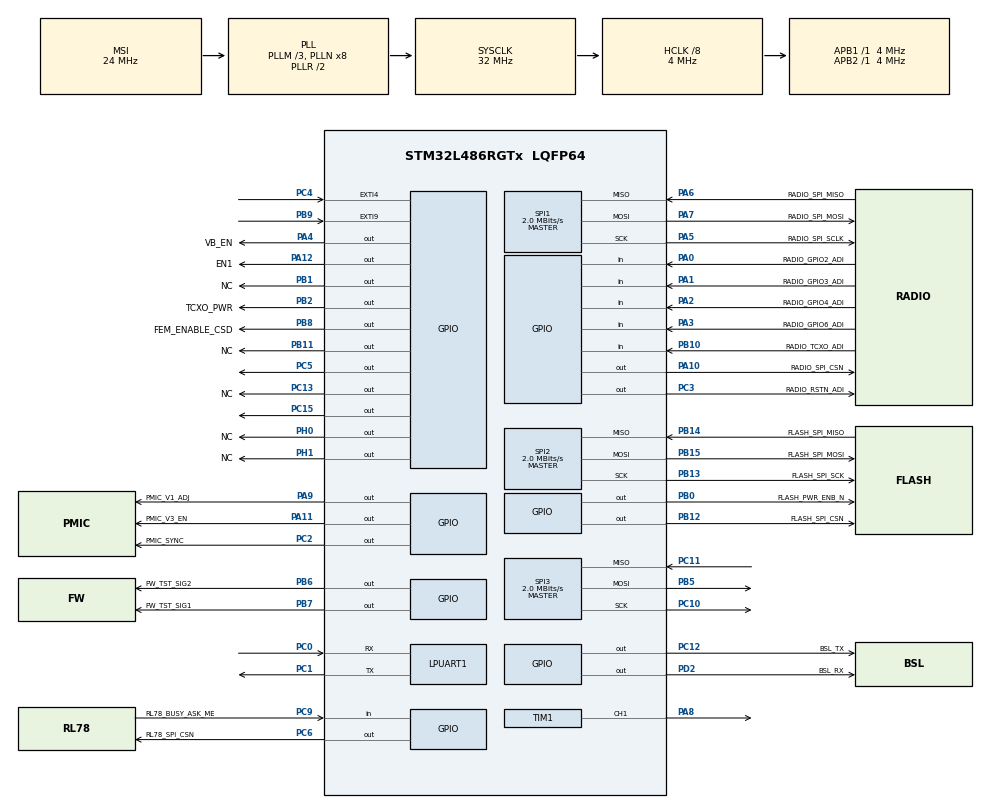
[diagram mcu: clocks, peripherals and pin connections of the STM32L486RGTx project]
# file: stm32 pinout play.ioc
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ADC1.Channel-0\#ChannelRegularConversion=ADC_CHANNEL_TEMPSENSOR
ADC1.NbrOfConversionFlag=1
ADC1.OffsetNumber-0\#ChannelRegularConversion=ADC_OFFSET_NONE
ADC1.Rank-0\#ChannelRegularConversion=1
ADC1.SamplingTime-0\#ChannelRegularConversion=ADC_SAMPLETIME_2CYCLES_5
ADC1.master=1
Mcu.Family=STM32L4
Mcu.Name=STM32L486RGTx
Mcu.Package=LQFP64
NVIC.EXTI4_IRQn=true\:0\:0\:false\:false\:true\:true
NVIC.PriorityGroup=NVIC_PRIORITYGROUP_4
PA0.GPIO_Label=RADIO_GPIO2_ADI
PA0.Signal=GPIO_Input
PA1.GPIO_Label=RADIO_GPIO3_ADI
PA1.Signal=GPIO_Input
PA10.GPIO_Label=RADIO_SPI_CSN
PA10.Signal=GPIO_Output
PA11.GPIO_Label=PMIC_V3_EN
PA11.Signal=GPIO_Output
PA12.GPIO_Label=EN1
PA12.Signal=GPIO_Output
PA13\ (JTMS-SWDIO).Mode=JTAG_5_pins
PA13\ (JTMS-SWDIO).Signal=SYS_JTMS-SWDIO
PA14\ (JTCK-SWCLK).Mode=JTAG_5_pins
PA14\ (JTCK-SWCLK).Signal=SYS_JTCK-SWCLK
PA15\ (JTDI).Mode=JTAG_5_pins
PA15\ (JTDI).Signal=SYS_JTDI
PA2.GPIO_Label=RADIO_GPIO4_ADI
PA2.Signal=GPIO_Input
PA3.GPIO_Label=RADIO_GPIO6_ADI
PA3.Signal=GPIO_Input
PA4.GPIO_Label=VB_EN
PA4.GPIO_PuPd=GPIO_PULLDOWN
PA4.GPIO_Speed=GPIO_SPEED_FREQ_LOW
PA4.Signal=GPIO_Output
PA5.GPIO_Label=RADIO_SPI_SCLK
PA5.Mode=Full_Duplex_Master
PA5.Signal=SPI1_SCK
PA6.GPIO_Label=RADIO_SPI_MISO
PA6.Mode=Full_Duplex_Master
PA6.Signal=SPI1_MISO
PA7.GPIO_Label=RADIO_SPI_MOSI
PA7.Mode=Full_Duplex_Master
PA7.Signal=SPI1_MOSI
PA8.Signal=S_TIM1_CH1
PA9.GPIO_Label=PMIC_V1_ADJ
PA9.GPIO_PuPd=GPIO_PULLDOWN
PA9.Signal=GPIO_Output
PB0.GPIO_Label=FLASH_PWR_ENB_N
PB0.PinState=GPIO_PIN_SET
PB0.Signal=GPIO_Output
PB1.GPIO_Label=NC
PB1.GPIO_PuPd=GPIO_PULLDOWN
PB1.Signal=GPIO_Output
PB10.GPIO_Label=RADIO_TCXO_ADI
PB10.GPIO_PuPd=GPIO_PULLDOWN
PB10.Signal=GPIO_Input
PB11.GPIO_Label=NC
PB11.GPIO_PuPd=GPIO_PULLDOWN
PB11.Signal=GPIO_Output
PB12.GPIO_Label=FLASH_SPI_CSN
PB12.Signal=GPIO_Output
PB13.GPIO_Label=FLASH_SPI_SCK
PB13.Mode=Full_Duplex_Master
PB13.Signal=SPI2_SCK
PB14.GPIO_Label=FLASH_SPI_MISO
PB14.Mode=Full_Duplex_Master
PB14.Signal=SPI2_MISO
PB15.GPIO_Label=FLASH_SPI_MOSI
PB15.Mode=Full_Duplex_Master
PB15.Signal=SPI2_MOSI
PB2.GPIO_Label=TCXO_PWR
PB2.PinState=GPIO_PIN_RESET
PB2.Signal=GPIO_Output
PB3\ (JTDO-TRACESWO).Mode=JTAG_5_pins
PB3\ (JTDO-TRACESWO).Signal=SYS_JTDO-SWO
PB4\ (NJTRST).Mode=JTAG_5_pins
PB4\ (NJTRST).Signal=SYS_JTRST
PB5.Mode=Full_Duplex_Master
PB5.Signal=SPI3_MOSI
PB6.GPIO_Label=FW_TST_SIG2
PB6.GPIO_PuPd=GPIO_PULLDOWN
PB6.Signal=GPIO_Output
PB7.GPIO_Label=FW_TST_SIG1
PB7.GPIO_PuPd=GPIO_PULLDOWN
PB7.Signal=GPIO_Output
PB8.GPIO_Label=FEM_ENABLE_CSD
PB8.GPIO_PuPd=GPIO_PULLDOWN
PB8.Signal=GPIO_Output
PB9.Signal=GPXTI9
PC0.Mode=Asynchronous
PC0.Signal=LPUART1_RX
PC1.Mode=Asynchronous
PC1.Signal=LPUART1_TX
PC10.Mode=Full_Duplex_Master
PC10.Signal=SPI3_SCK
PC11.Mode=Full_Duplex_Master
PC11.Signal=SPI3_MISO
PC12.GPIO_Label=BSL_TX
PC12.GPIO_PuPd=GPIO_PULLDOWN
PC12.Signal=GPIO_Output
PC13.GPIO_Label=NC
PC13.GPIO_PuPd=GPIO_PULLDOWN
PC13.Signal=GPIO_Output
PC14-OSC32_IN\ (PC14).Mode=LSE-External-Clock-Source
PC14-OSC32_IN\ (PC14).Signal=RCC_OSC32_IN
PC15-OSC32_OUT\ (PC15).Signal=GPIO_Output
PC2.GPIO_Label=PMIC_SYNC
PC2.GPIO_ModeDefaultOutputPP=GPIO_MODE_OUTPUT_PP
PC2.Signal=GPIO_Output
PC3.GPIO_Label=RADIO_RSTN_ADI
PC3.Signal=GPIO_Output
PC4.Signal=GPXTI4
PC5.GPIO_PuPd=GPIO_PULLDOWN
PC5.Signal=GPIO_Output
PC6.GPIO_Label=RL78_SPI_CSN
PC6.GPIO_PuPd=GPIO_PULLDOWN
PC6.Signal=GPIO_Output
PC7.Signal=S_TIM3_CH2
PC8.Signal=S_TIM3_CH3
PC9.GPIO_Label=RL78_BUSY_ASK_ME
PC9.Signal=GPIO_Input
PD2.GPIO_Label=BSL_RX
PD2.GPIO_PuPd=GPIO_PULLDOWN
PD2.Signal=GPIO_Output
PH0-OSC_IN\ (PH0).GPIO_Label=NC
PH0-OSC_IN\ (PH0).GPIO_PuPd=GPIO_PULLDOWN
PH0-OSC_IN\ (PH0).Signal=GPIO_Output
PH1-OSC_OUT\ (PH1).GPIO_Label=NC
PH1-OSC_OUT\ (PH1).GPIO_PuPd=GPIO_PULLDOWN
PH1-OSC_OUT\ (PH1).Signal=GPIO_Output
ProjectManager.HeapSize=0x200
ProjectManager.StackSize=0x400
ProjectManager.TargetToolchain=MDK-ARM V5
RCC.ADCFreq_Value=64000000
RCC.AHBCLKDivider=RCC_SYSCLK_DIV8
RCC.AHBFreq_Value=4000000
RCC.APB1Freq_Value=4000000
RCC.APB1TimFreq_Value=4000000
RCC.APB2Freq_Value=4000000
RCC.APB2TimFreq_Value=4000000
RCC.CortexFreq_Value=4000000
RCC.HCLKFreq_Value=4000000
RCC.HSE_VALUE=8000000
RCC.HSI_VALUE=16000000
RCC.MSIClockRange=RCC_MSIRANGE_9
RCC.MSI_VALUE=24000000
RCC.PLLM=3
RCC.PLLSAI1N=16
RCC.RTCClockSelection=RCC_RTCCLKSOURCE_LSE
RCC.SYSCLKFreq_VALUE=32000000
RCC.SYSCLKSource=RCC_SYSCLKSOURCE_PLLCLK
RCC.USBFreq_Value=64000000
RCC.VCOOutputFreq_Value=64000000
SH.S_TIM1_CH1.0=TIM1_CH1,Output Compare1 CH1
SH.S_TIM3_CH2.0=TIM3_CH2
SH.S_TIM3_CH3.0=TIM3_CH3
SPI1.CalculateBaudRate=2.0 MBits/s
SPI1.Direction=SPI_DIRECTION_2LINES
SPI1.Mode=SPI_MODE_MASTER
SPI1.VirtualType=VM_MASTER
SPI2.CalculateBaudRate=2.0 MBits/s
SPI2.Direction=SPI_DIRECTION_2LINES
SPI2.Mode=SPI_MODE_MASTER
SPI2.VirtualType=VM_MASTER
SPI3.CalculateBaudRate=2.0 MBits/s
SPI3.Direction=SPI_DIRECTION_2LINES
SPI3.Mode=SPI_MODE_MASTER
SPI3.VirtualType=VM_MASTER
TIM1.Channel-Output\ Compare1\ CH1=TIM_CHANNEL_1
TIM1.OCMode_1=TIM_OCMODE_RETRIGERRABLE_OPM2
TIM1.Period=8191
TIM1.Pulse-Output\ Compare1\ CH1=8191
VP_ADC1_TempSens_Input.Mode=IN-TempSens
VP_RTC_VS_RTC_Activate.Mode=RTC_Enabled
VP_TIM1_VS_ClockSourceINT.Mode=Internal
board=custom

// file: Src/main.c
/**
  ******************************************************************************
  * @file           : main.c
  * @brief          : Main program body
  ******************************************************************************
  ** This notice applies to any and all portions of this file
  * that are not between comment pairs USER CODE BEGIN and
  * USER CODE END. Other portions of this file, whether
  * inserted by the user or by software development tools
  * are owned by their respective copyright owners.
  *
  * COPYRIGHT(c) 2019 STMicroelectronics
  *
  * Redistribution and use in source and binary forms, with or without modification,
  * are permitted provided that the following conditions are met:
  *   1. Redistributions of source code must retain the above copyright notice,
  *      this list of conditions and the following disclaimer.
  *   2. Redistributions in binary form must reproduce the above copyright notice,
  *      this list of conditions and the following disclaimer in the documentation
  *      and/or other materials provided with the distribution.
  *   3. Neither the name of STMicroelectronics nor the names of its contributors
  *      may be used to endorse or promote products derived from this software
  *      without specific prior written permission.
  *
  * THIS SOFTWARE IS PROVIDED BY THE COPYRIGHT HOLDERS AND CONTRIBUTORS "AS IS"
  * AND ANY EXPRESS OR IMPLIED WARRANTIES, INCLUDING, BUT NOT LIMITED TO, THE
  * IMPLIED WARRANTIES OF MERCHANTABILITY AND FITNESS FOR A PARTICULAR PURPOSE ARE
  * DISCLAIMED. IN NO EVENT SHALL THE COPYRIGHT HOLDER OR CONTRIBUTORS BE LIABLE
  * FOR ANY DIRECT, INDIRECT, INCIDENTAL, SPECIAL, EXEMPLARY, OR CONSEQUENTIAL
  * DAMAGES (INCLUDING, BUT NOT LIMITED TO, PROCUREMENT OF SUBSTITUTE GOODS OR
  * SERVICES; LOSS OF USE, DATA, OR PROFITS; OR BUSINESS INTERRUPTION) HOWEVER
  * CAUSED AND ON ANY THEORY OF LIABILITY, WHETHER IN CONTRACT, STRICT LIABILITY,
  * OR TORT (INCLUDING NEGLIGENCE OR OTHERWISE) ARISING IN ANY WAY OUT OF THE USE
  * OF THIS SOFTWARE, EVEN IF ADVISED OF THE POSSIBILITY OF SUCH DAMAGE.
  *
  ******************************************************************************
  */
#include "main.h"
#include "stm32l4xx_hal.h"

ADC_HandleTypeDef hadc1;

UART_HandleTypeDef hlpuart1;

RTC_HandleTypeDef hrtc;

SPI_HandleTypeDef hspi1;
SPI_HandleTypeDef hspi2;
SPI_HandleTypeDef hspi3;

TIM_HandleTypeDef htim1;

/* USER CODE BEGIN PV */
/* Private variables ---------------------------------------------------------*/

/* USER CODE END PV */

void SystemClock_Config(void);
static void MX_GPIO_Init(void);
static void MX_ADC1_Init(void);
static void MX_LPUART1_UART_Init(void);
static void MX_SPI1_Init(void);
static void MX_SPI2_Init(void);
static void MX_SPI3_Init(void);
static void MX_RTC_Init(void);
static void MX_TIM1_Init(void);

void HAL_TIM_MspPostInit(TIM_HandleTypeDef *htim);

/* USER CODE BEGIN PFP */
/* Private function prototypes -----------------------------------------------*/

/* USER CODE END PFP */

int main(void)
{

  /* MCU Configuration----------------------------------------------------------*/

  /* Reset of all peripherals, Initializes the Flash interface and the Systick. */
  HAL_Init();

  /* Configure the system clock */
  SystemClock_Config();

  /* Initialize all configured peripherals */
  MX_GPIO_Init();
  MX_ADC1_Init();
  MX_LPUART1_UART_Init();
  MX_SPI1_Init();
  MX_SPI2_Init();
  MX_SPI3_Init();
  MX_RTC_Init();
  MX_TIM1_Init();
  /* USER CODE BEGIN 2 */
	HAL_TIM_OC_Start(&htim1, TIM_CHANNEL_1);
  /* USER CODE END 2 */

  /* Infinite loop */
  while (1)
  {

  /* USER CODE BEGIN 3 */
	HAL_GPIO_TogglePin(GPIOC, GPIO_PIN_12);
	HAL_Delay(500);
  }
  /* USER CODE END 3 */

}

void SystemClock_Config(void)
{

  RCC_OscInitTypeDef RCC_OscInitStruct;
  RCC_ClkInitTypeDef RCC_ClkInitStruct;
  RCC_PeriphCLKInitTypeDef PeriphClkInit;

    /**Initializes the CPU, AHB and APB busses clocks
    */
  RCC_OscInitStruct.OscillatorType = RCC_OSCILLATORTYPE_LSE|RCC_OSCILLATORTYPE_MSI;
  RCC_OscInitStruct.LSEState = RCC_LSE_BYPASS;
  RCC_OscInitStruct.MSIState = RCC_MSI_ON;
  RCC_OscInitStruct.MSICalibrationValue = 0;
  RCC_OscInitStruct.MSIClockRange = RCC_MSIRANGE_9;
  RCC_OscInitStruct.PLL.PLLState = RCC_PLL_ON;
  RCC_OscInitStruct.PLL.PLLSource = RCC_PLLSOURCE_MSI;
  RCC_OscInitStruct.PLL.PLLM = 3;
  RCC_OscInitStruct.PLL.PLLN = 8;
  RCC_OscInitStruct.PLL.PLLP = RCC_PLLP_DIV7;
  RCC_OscInitStruct.PLL.PLLQ = RCC_PLLQ_DIV2;
  RCC_OscInitStruct.PLL.PLLR = RCC_PLLR_DIV2;
  if (HAL_RCC_OscConfig(&RCC_OscInitStruct) != HAL_OK)
  {
    _Error_Handler(__FILE__, __LINE__);
  }

    /**Initializes the CPU, AHB and APB busses clocks
    */
  RCC_ClkInitStruct.ClockType = RCC_CLOCKTYPE_HCLK|RCC_CLOCKTYPE_SYSCLK
                              |RCC_CLOCKTYPE_PCLK1|RCC_CLOCKTYPE_PCLK2;
  RCC_ClkInitStruct.SYSCLKSource = RCC_SYSCLKSOURCE_PLLCLK;
  RCC_ClkInitStruct.AHBCLKDivider = RCC_SYSCLK_DIV8;
  RCC_ClkInitStruct.APB1CLKDivider = RCC_HCLK_DIV1;
  RCC_ClkInitStruct.APB2CLKDivider = RCC_HCLK_DIV1;

  if (HAL_RCC_ClockConfig(&RCC_ClkInitStruct, FLASH_LATENCY_0) != HAL_OK)
  {
    _Error_Handler(__FILE__, __LINE__);
  }

  PeriphClkInit.PeriphClockSelection = RCC_PERIPHCLK_RTC|RCC_PERIPHCLK_LPUART1
                              |RCC_PERIPHCLK_ADC;
  PeriphClkInit.Lpuart1ClockSelection = RCC_LPUART1CLKSOURCE_PCLK1;
  PeriphClkInit.AdcClockSelection = RCC_ADCCLKSOURCE_PLLSAI1;
  PeriphClkInit.RTCClockSelection = RCC_RTCCLKSOURCE_LSE;
  PeriphClkInit.PLLSAI1.PLLSAI1Source = RCC_PLLSOURCE_MSI;
  PeriphClkInit.PLLSAI1.PLLSAI1M = 3;
  PeriphClkInit.PLLSAI1.PLLSAI1N = 16;
  PeriphClkInit.PLLSAI1.PLLSAI1P = RCC_PLLP_DIV7;
  PeriphClkInit.PLLSAI1.PLLSAI1Q = RCC_PLLQ_DIV2;
  PeriphClkInit.PLLSAI1.PLLSAI1R = RCC_PLLR_DIV2;
  PeriphClkInit.PLLSAI1.PLLSAI1ClockOut = RCC_PLLSAI1_ADC1CLK;
  if (HAL_RCCEx_PeriphCLKConfig(&PeriphClkInit) != HAL_OK)
  {
    _Error_Handler(__FILE__, __LINE__);
  }

    /**Configure the main internal regulator output voltage
    */
  if (HAL_PWREx_ControlVoltageScaling(PWR_REGULATOR_VOLTAGE_SCALE1) != HAL_OK)
  {
    _Error_Handler(__FILE__, __LINE__);
  }

    /**Configure the Systick interrupt time
    */
  HAL_SYSTICK_Config(HAL_RCC_GetHCLKFreq()/1000);

    /**Configure the Systick
    */
  HAL_SYSTICK_CLKSourceConfig(SYSTICK_CLKSOURCE_HCLK);

    /**Enable MSI Auto calibration
    */
  HAL_RCCEx_EnableMSIPLLMode();

  /* SysTick_IRQn interrupt configuration */
  HAL_NVIC_SetPriority(SysTick_IRQn, 0, 0);
}

/* ADC1 init function */
static void MX_ADC1_Init(void)
{

  ADC_MultiModeTypeDef multimode;
  ADC_ChannelConfTypeDef sConfig;

    /**Common config
    */
  hadc1.Instance = ADC1;
  hadc1.Init.ClockPrescaler = ADC_CLOCK_ASYNC_DIV1;
  hadc1.Init.Resolution = ADC_RESOLUTION_12B;
  hadc1.Init.DataAlign = ADC_DATAALIGN_RIGHT;
  hadc1.Init.ScanConvMode = ADC_SCAN_DISABLE;
  hadc1.Init.EOCSelection = ADC_EOC_SINGLE_CONV;
  hadc1.Init.LowPowerAutoWait = DISABLE;
  hadc1.Init.ContinuousConvMode = DISABLE;
  hadc1.Init.NbrOfConversion = 1;
  hadc1.Init.DiscontinuousConvMode = DISABLE;
  hadc1.Init.ExternalTrigConv = ADC_SOFTWARE_START;
  hadc1.Init.ExternalTrigConvEdge = ADC_EXTERNALTRIGCONVEDGE_NONE;
  hadc1.Init.DMAContinuousRequests = DISABLE;
  hadc1.Init.Overrun = ADC_OVR_DATA_PRESERVED;
  hadc1.Init.OversamplingMode = DISABLE;
  if (HAL_ADC_Init(&hadc1) != HAL_OK)
  {
    _Error_Handler(__FILE__, __LINE__);
  }

    /**Configure the ADC multi-mode
    */
  multimode.Mode = ADC_MODE_INDEPENDENT;
  if (HAL_ADCEx_MultiModeConfigChannel(&hadc1, &multimode) != HAL_OK)
  {
    _Error_Handler(__FILE__, __LINE__);
  }

    /**Configure Regular Channel
    */
  sConfig.Channel = ADC_CHANNEL_TEMPSENSOR;
  sConfig.Rank = ADC_REGULAR_RANK_1;
  sConfig.SamplingTime = ADC_SAMPLETIME_2CYCLES_5;
  sConfig.SingleDiff = ADC_SINGLE_ENDED;
  sConfig.OffsetNumber = ADC_OFFSET_NONE;
  sConfig.Offset = 0;
  if (HAL_ADC_ConfigChannel(&hadc1, &sConfig) != HAL_OK)
  {
    _Error_Handler(__FILE__, __LINE__);
  }

}

/* LPUART1 init function */
static void MX_LPUART1_UART_Init(void)
{

  hlpuart1.Instance = LPUART1;
  hlpuart1.Init.BaudRate = 209700;
  hlpuart1.Init.WordLength = UART_WORDLENGTH_7B;
  hlpuart1.Init.StopBits = UART_STOPBITS_1;
  hlpuart1.Init.Parity = UART_PARITY_NONE;
  hlpuart1.Init.Mode = UART_MODE_TX_RX;
  hlpuart1.Init.HwFlowCtl = UART_HWCONTROL_NONE;
  hlpuart1.Init.OneBitSampling = UART_ONE_BIT_SAMPLE_DISABLE;
  hlpuart1.AdvancedInit.AdvFeatureInit = UART_ADVFEATURE_NO_INIT;
  if (HAL_UART_Init(&hlpuart1) != HAL_OK)
  {
    _Error_Handler(__FILE__, __LINE__);
  }

}

/* RTC init function */
static void MX_RTC_Init(void)
{

    /**Initialize RTC Only
    */
  hrtc.Instance = RTC;
  hrtc.Init.HourFormat = RTC_HOURFORMAT_24;
  hrtc.Init.AsynchPrediv = 127;
  hrtc.Init.SynchPrediv = 255;
  hrtc.Init.OutPut = RTC_OUTPUT_DISABLE;
  hrtc.Init.OutPutRemap = RTC_OUTPUT_REMAP_NONE;
  hrtc.Init.OutPutPolarity = RTC_OUTPUT_POLARITY_HIGH;
  hrtc.Init.OutPutType = RTC_OUTPUT_TYPE_OPENDRAIN;
  if (HAL_RTC_Init(&hrtc) != HAL_OK)
  {
    _Error_Handler(__FILE__, __LINE__);
  }

}

/* SPI1 init function */
static void MX_SPI1_Init(void)
{

  /* SPI1 parameter configuration*/
  hspi1.Instance = SPI1;
  hspi1.Init.Mode = SPI_MODE_MASTER;
  hspi1.Init.Direction = SPI_DIRECTION_2LINES;
  hspi1.Init.DataSize = SPI_DATASIZE_4BIT;
  hspi1.Init.CLKPolarity = SPI_POLARITY_LOW;
  hspi1.Init.CLKPhase = SPI_PHASE_1EDGE;
  hspi1.Init.NSS = SPI_NSS_SOFT;
  hspi1.Init.BaudRatePrescaler = SPI_BAUDRATEPRESCALER_2;
  hspi1.Init.FirstBit = SPI_FIRSTBIT_MSB;
  hspi1.Init.TIMode = SPI_TIMODE_DISABLE;
  hspi1.Init.CRCCalculation = SPI_CRCCALCULATION_DISABLE;
  hspi1.Init.CRCPolynomial = 7;
  hspi1.Init.CRCLength = SPI_CRC_LENGTH_DATASIZE;
  hspi1.Init.NSSPMode = SPI_NSS_PULSE_ENABLE;
  if (HAL_SPI_Init(&hspi1) != HAL_OK)
  {
    _Error_Handler(__FILE__, __LINE__);
  }

}

/* SPI2 init function */
static void MX_SPI2_Init(void)
{

  /* SPI2 parameter configuration*/
  hspi2.Instance = SPI2;
  hspi2.Init.Mode = SPI_MODE_MASTER;
  hspi2.Init.Direction = SPI_DIRECTION_2LINES;
  hspi2.Init.DataSize = SPI_DATASIZE_4BIT;
  hspi2.Init.CLKPolarity = SPI_POLARITY_LOW;
  hspi2.Init.CLKPhase = SPI_PHASE_1EDGE;
  hspi2.Init.NSS = SPI_NSS_SOFT;
  hspi2.Init.BaudRatePrescaler = SPI_BAUDRATEPRESCALER_2;
  hspi2.Init.FirstBit = SPI_FIRSTBIT_MSB;
  hspi2.Init.TIMode = SPI_TIMODE_DISABLE;
  hspi2.Init.CRCCalculation = SPI_CRCCALCULATION_DISABLE;
  hspi2.Init.CRCPolynomial = 7;
  hspi2.Init.CRCLength = SPI_CRC_LENGTH_DATASIZE;
  hspi2.Init.NSSPMode = SPI_NSS_PULSE_ENABLE;
  if (HAL_SPI_Init(&hspi2) != HAL_OK)
  {
    _Error_Handler(__FILE__, __LINE__);
  }

}

/* SPI3 init function */
static void MX_SPI3_Init(void)
{

  /* SPI3 parameter configuration*/
  hspi3.Instance = SPI3;
  hspi3.Init.Mode = SPI_MODE_MASTER;
  hspi3.Init.Direction = SPI_DIRECTION_2LINES;
  hspi3.Init.DataSize = SPI_DATASIZE_4BIT;
  hspi3.Init.CLKPolarity = SPI_POLARITY_LOW;
  hspi3.Init.CLKPhase = SPI_PHASE_1EDGE;
  hspi3.Init.NSS = SPI_NSS_SOFT;
  hspi3.Init.BaudRatePrescaler = SPI_BAUDRATEPRESCALER_2;
  hspi3.Init.FirstBit = SPI_FIRSTBIT_MSB;
  hspi3.Init.TIMode = SPI_TIMODE_DISABLE;
  hspi3.Init.CRCCalculation = SPI_CRCCALCULATION_DISABLE;
  hspi3.Init.CRCPolynomial = 7;
  hspi3.Init.CRCLength = SPI_CRC_LENGTH_DATASIZE;
  hspi3.Init.NSSPMode = SPI_NSS_PULSE_ENABLE;
  if (HAL_SPI_Init(&hspi3) != HAL_OK)
  {
    _Error_Handler(__FILE__, __LINE__);
  }

}

/* TIM1 init function */
static void MX_TIM1_Init(void)
{

  TIM_ClockConfigTypeDef sClockSourceConfig;
  TIM_MasterConfigTypeDef sMasterConfig;
  TIM_OC_InitTypeDef sConfigOC;
  TIM_BreakDeadTimeConfigTypeDef sBreakDeadTimeConfig;

  htim1.Instance = TIM1;
  htim1.Init.Prescaler = 0;
  htim1.Init.CounterMode = TIM_COUNTERMODE_UP;
  htim1.Init.Period = 8191;
  htim1.Init.ClockDivision = TIM_CLOCKDIVISION_DIV1;
  htim1.Init.RepetitionCounter = 0;
  htim1.Init.AutoReloadPreload = TIM_AUTORELOAD_PRELOAD_DISABLE;
  if (HAL_TIM_Base_Init(&htim1) != HAL_OK)
  {
    _Error_Handler(__FILE__, __LINE__);
  }

  sClockSourceConfig.ClockSource = TIM_CLOCKSOURCE_INTERNAL;
  if (HAL_TIM_ConfigClockSource(&htim1, &sClockSourceConfig) != HAL_OK)
  {
    _Error_Handler(__FILE__, __LINE__);
  }

  if (HAL_TIM_OC_Init(&htim1) != HAL_OK)
  {
    _Error_Handler(__FILE__, __LINE__);
  }

  sMasterConfig.MasterOutputTrigger = TIM_TRGO_RESET;
  sMasterConfig.MasterOutputTrigger2 = TIM_TRGO2_RESET;
  sMasterConfig.MasterSlaveMode = TIM_MASTERSLAVEMODE_DISABLE;
  if (HAL_TIMEx_MasterConfigSynchronization(&htim1, &sMasterConfig) != HAL_OK)
  {
    _Error_Handler(__FILE__, __LINE__);
  }

  sConfigOC.OCMode = TIM_OCMODE_PWM2;
  sConfigOC.Pulse = 8191;
  sConfigOC.OCPolarity = TIM_OCPOLARITY_HIGH;
  sConfigOC.OCNPolarity = TIM_OCNPOLARITY_HIGH;
  sConfigOC.OCFastMode = TIM_OCFAST_DISABLE;
  sConfigOC.OCIdleState = TIM_OCIDLESTATE_RESET;
  sConfigOC.OCNIdleState = TIM_OCNIDLESTATE_RESET;
  if (HAL_TIM_OC_ConfigChannel(&htim1, &sConfigOC, TIM_CHANNEL_1) != HAL_OK)
  {
    _Error_Handler(__FILE__, __LINE__);
  }

  sBreakDeadTimeConfig.OffStateRunMode = TIM_OSSR_DISABLE;
  sBreakDeadTimeConfig.OffStateIDLEMode = TIM_OSSI_DISABLE;
  sBreakDeadTimeConfig.LockLevel = TIM_LOCKLEVEL_OFF;
  sBreakDeadTimeConfig.DeadTime = 0;
  sBreakDeadTimeConfig.BreakState = TIM_BREAK_DISABLE;
  sBreakDeadTimeConfig.BreakPolarity = TIM_BREAKPOLARITY_HIGH;
  sBreakDeadTimeConfig.BreakFilter = 0;
  sBreakDeadTimeConfig.Break2State = TIM_BREAK2_DISABLE;
  sBreakDeadTimeConfig.Break2Polarity = TIM_BREAK2POLARITY_HIGH;
  sBreakDeadTimeConfig.Break2Filter = 0;
  sBreakDeadTimeConfig.AutomaticOutput = TIM_AUTOMATICOUTPUT_DISABLE;
  if (HAL_TIMEx_ConfigBreakDeadTime(&htim1, &sBreakDeadTimeConfig) != HAL_OK)
  {
    _Error_Handler(__FILE__, __LINE__);
  }

  HAL_TIM_MspPostInit(&htim1);

}

/** Configure pins as
        * Analog
        * Input
        * Output
        * EVENT_OUT
        * EXTI
     PC7   ------> S_TIM3_CH2
     PC8   ------> S_TIM3_CH3
*/
static void MX_GPIO_Init(void)
{

  GPIO_InitTypeDef GPIO_InitStruct;

  /* GPIO Ports Clock Enable */
  __HAL_RCC_GPIOC_CLK_ENABLE();
  __HAL_RCC_GPIOH_CLK_ENABLE();
  __HAL_RCC_GPIOA_CLK_ENABLE();
  __HAL_RCC_GPIOB_CLK_ENABLE();
  __HAL_RCC_GPIOD_CLK_ENABLE();

  /*Configure GPIO pin Output Level */
  HAL_GPIO_WritePin(GPIOC, NC_Pin|GPIO_PIN_15|PMIC_SYNC_Pin|RADIO_RSTN_ADI_Pin
                          |GPIO_PIN_5|RL78_SPI_CSN_Pin|BSL_TX_Pin, GPIO_PIN_RESET);

  /*Configure GPIO pin Output Level */
  HAL_GPIO_WritePin(GPIOH, NCH0_Pin|NCH1_Pin, GPIO_PIN_RESET);

  /*Configure GPIO pin Output Level */
  HAL_GPIO_WritePin(GPIOA, VB_EN_Pin|PMIC_V1_ADJ_Pin|RADIO_SPI_CSN_Pin|PMIC_V3_EN_Pin
                          |EN1_Pin, GPIO_PIN_RESET);

  /*Configure GPIO pin Output Level */
  HAL_GPIO_WritePin(FLASH_PWR_ENB_N_GPIO_Port, FLASH_PWR_ENB_N_Pin, GPIO_PIN_SET);

  /*Configure GPIO pin Output Level */
  HAL_GPIO_WritePin(GPIOB, NCB1_Pin|TCXO_PWR_Pin|NCB11_Pin|FLASH_SPI_CSN_Pin
                          |FW_TST_SIG2_Pin|FW_TST_SIG1_Pin|FEM_ENABLE_CSD_Pin, GPIO_PIN_RESET);

  /*Configure GPIO pin Output Level */
  HAL_GPIO_WritePin(BSL_RX_GPIO_Port, BSL_RX_Pin, GPIO_PIN_RESET);

  /*Configure GPIO pins : NC_Pin PC5 RL78_SPI_CSN_Pin BSL_TX_Pin */
  GPIO_InitStruct.Pin = NC_Pin|GPIO_PIN_5|RL78_SPI_CSN_Pin|BSL_TX_Pin;
  GPIO_InitStruct.Mode = GPIO_MODE_OUTPUT_PP;
  GPIO_InitStruct.Pull = GPIO_PULLDOWN;
  GPIO_InitStruct.Speed = GPIO_SPEED_FREQ_LOW;
  HAL_GPIO_Init(GPIOC, &GPIO_InitStruct);

  /*Configure GPIO pins : PC15 PMIC_SYNC_Pin RADIO_RSTN_ADI_Pin */
  GPIO_InitStruct.Pin = GPIO_PIN_15|PMIC_SYNC_Pin|RADIO_RSTN_ADI_Pin;
  GPIO_InitStruct.Mode = GPIO_MODE_OUTPUT_PP;
  GPIO_InitStruct.Pull = GPIO_NOPULL;
  GPIO_InitStruct.Speed = GPIO_SPEED_FREQ_LOW;
  HAL_GPIO_Init(GPIOC, &GPIO_InitStruct);

  /*Configure GPIO pins : NCH0_Pin NCH1_Pin */
  GPIO_InitStruct.Pin = NCH0_Pin|NCH1_Pin;
  GPIO_InitStruct.Mode = GPIO_MODE_OUTPUT_PP;
  GPIO_InitStruct.Pull = GPIO_PULLDOWN;
  GPIO_InitStruct.Speed = GPIO_SPEED_FREQ_LOW;
  HAL_GPIO_Init(GPIOH, &GPIO_InitStruct);

  /*Configure GPIO pins : RADIO_GPIO2_ADI_Pin RADIO_GPIO3_ADI_Pin RADIO_GPIO4_ADI_Pin RADIO_GPIO6_ADI_Pin */
  GPIO_InitStruct.Pin = RADIO_GPIO2_ADI_Pin|RADIO_GPIO3_ADI_Pin|RADIO_GPIO4_ADI_Pin|RADIO_GPIO6_ADI_Pin;
  GPIO_InitStruct.Mode = GPIO_MODE_INPUT;
  GPIO_InitStruct.Pull = GPIO_NOPULL;
  HAL_GPIO_Init(GPIOA, &GPIO_InitStruct);

  /*Configure GPIO pins : VB_EN_Pin PMIC_V1_ADJ_Pin */
  GPIO_InitStruct.Pin = VB_EN_Pin|PMIC_V1_ADJ_Pin;
  GPIO_InitStruct.Mode = GPIO_MODE_OUTPUT_PP;
  GPIO_InitStruct.Pull = GPIO_PULLDOWN;
  GPIO_InitStruct.Speed = GPIO_SPEED_FREQ_LOW;
  HAL_GPIO_Init(GPIOA, &GPIO_InitStruct);

  /*Configure GPIO pin : PC4 */
  GPIO_InitStruct.Pin = GPIO_PIN_4;
  GPIO_InitStruct.Mode = GPIO_MODE_IT_RISING;
  GPIO_InitStruct.Pull = GPIO_NOPULL;
  HAL_GPIO_Init(GPIOC, &GPIO_InitStruct);

  /*Configure GPIO pins : FLASH_PWR_ENB_N_Pin TCXO_PWR_Pin FLASH_SPI_CSN_Pin */
  GPIO_InitStruct.Pin = FLASH_PWR_ENB_N_Pin|TCXO_PWR_Pin|FLASH_SPI_CSN_Pin;
  GPIO_InitStruct.Mode = GPIO_MODE_OUTPUT_PP;
  GPIO_InitStruct.Pull = GPIO_NOPULL;
  GPIO_InitStruct.Speed = GPIO_SPEED_FREQ_LOW;
  HAL_GPIO_Init(GPIOB, &GPIO_InitStruct);

  /*Configure GPIO pins : NCB1_Pin NCB11_Pin FW_TST_SIG2_Pin FW_TST_SIG1_Pin
                           FEM_ENABLE_CSD_Pin */
  GPIO_InitStruct.Pin = NCB1_Pin|NCB11_Pin|FW_TST_SIG2_Pin|FW_TST_SIG1_Pin
                          |FEM_ENABLE_CSD_Pin;
  GPIO_InitStruct.Mode = GPIO_MODE_OUTPUT_PP;
  GPIO_InitStruct.Pull = GPIO_PULLDOWN;
  GPIO_InitStruct.Speed = GPIO_SPEED_FREQ_LOW;
  HAL_GPIO_Init(GPIOB, &GPIO_InitStruct);

  /*Configure GPIO pin : RADIO_TCXO_ADI_Pin */
  GPIO_InitStruct.Pin = RADIO_TCXO_ADI_Pin;
  GPIO_InitStruct.Mode = GPIO_MODE_INPUT;
  GPIO_InitStruct.Pull = GPIO_PULLDOWN;
  HAL_GPIO_Init(RADIO_TCXO_ADI_GPIO_Port, &GPIO_InitStruct);

  /*Configure GPIO pins : PC7 PC8 */
  GPIO_InitStruct.Pin = GPIO_PIN_7|GPIO_PIN_8;
  GPIO_InitStruct.Mode = GPIO_MODE_AF_PP;
  GPIO_InitStruct.Pull = GPIO_NOPULL;
  GPIO_InitStruct.Speed = GPIO_SPEED_FREQ_LOW;
  GPIO_InitStruct.Alternate = GPIO_AF2_TIM3;
  HAL_GPIO_Init(GPIOC, &GPIO_InitStruct);

  /*Configure GPIO pin : RL78_BUSY_ASK_ME_Pin */
  GPIO_InitStruct.Pin = RL78_BUSY_ASK_ME_Pin;
  GPIO_InitStruct.Mode = GPIO_MODE_INPUT;
  GPIO_InitStruct.Pull = GPIO_NOPULL;
  HAL_GPIO_Init(RL78_BUSY_ASK_ME_GPIO_Port, &GPIO_InitStruct);

  /*Configure GPIO pins : RADIO_SPI_CSN_Pin PMIC_V3_EN_Pin EN1_Pin */
  GPIO_InitStruct.Pin = RADIO_SPI_CSN_Pin|PMIC_V3_EN_Pin|EN1_Pin;
  GPIO_InitStruct.Mode = GPIO_MODE_OUTPUT_PP;
  GPIO_InitStruct.Pull = GPIO_NOPULL;
  GPIO_InitStruct.Speed = GPIO_SPEED_FREQ_LOW;
  HAL_GPIO_Init(GPIOA, &GPIO_InitStruct);

  /*Configure GPIO pin : BSL_RX_Pin */
  GPIO_InitStruct.Pin = BSL_RX_Pin;
  GPIO_InitStruct.Mode = GPIO_MODE_OUTPUT_PP;
  GPIO_InitStruct.Pull = GPIO_PULLDOWN;
  GPIO_InitStruct.Speed = GPIO_SPEED_FREQ_LOW;
  HAL_GPIO_Init(BSL_RX_GPIO_Port, &GPIO_InitStruct);

  /*Configure GPIO pin : PB9 */
  GPIO_InitStruct.Pin = GPIO_PIN_9;
  GPIO_InitStruct.Mode = GPIO_MODE_IT_RISING;
  GPIO_InitStruct.Pull = GPIO_NOPULL;
  HAL_GPIO_Init(GPIOB, &GPIO_InitStruct);

  /* EXTI interrupt init*/
  HAL_NVIC_SetPriority(EXTI4_IRQn, 0, 0);
  HAL_NVIC_EnableIRQ(EXTI4_IRQn);

}

/* USER CODE BEGIN 4 */
void HAL_GPIO_EXTI_Callback(uint16_t GPIO_Pin)
{
  /* Prevent unused argument(s) compilation warning */
  UNUSED(GPIO_Pin);

 HAL_Delay(2);
}
/* USER CODE END 4 */

void _Error_Handler(char *file, int line)
{
  while(1)
  {
  }
}

/************************ (C) COPYRIGHT STMicroelectronics *****END OF FILE****/
